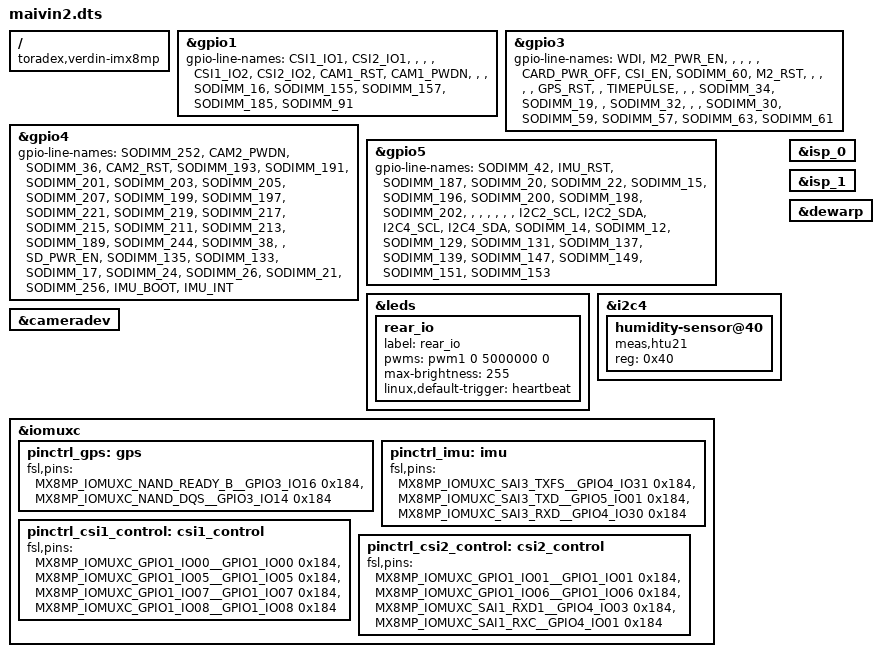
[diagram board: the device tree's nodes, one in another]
// SPDX-License-Identifier: AGPL-3.0
/*
 * Copyright 2023 Au-Zone Technologies
 */

// Maivin 2 Overlays

/dts-v1/;
/plugin/;

#include <dt-bindings/clock/imx8mp-clock.h>
#include <dt-bindings/gpio/gpio.h>

#include "imx8mp-pinfunc.h"

/ {
	compatible = "toradex,verdin-imx8mp";
};

&gpio1 {
	gpio-line-names = "CSI1_IO1", /* SODIMM_206 */
			  "CSI2_IO1", /* SODIMM_208 */
			  "",
			  "",
			  "",
			  "CSI1_IO2", /* SODIMM_210 */
			  "CSI2_IO2", /* SODIMM_212 */
			  "CAM1_RST", /* SODIMM_216 */
			  "CAM1_PWDN", /* SODIMM_218 */
			  "",
			  "",
			  "SODIMM_16",
			  "SODIMM_155",
			  "SODIMM_157",
			  "SODIMM_185",
			  "SODIMM_91";
};

&gpio3 {
	gpio-line-names = "WDI", /* SODIMM_52 */
			  "M2_PWR_EN", /* SODIMM_54 */
			  "",
			  "",
			  "",
			  "",
			  "CARD_PWR_OFF", /* SODIMM_56 */
			  "CSI_EN", /* SODIMM_58 */
			  "SODIMM_60",
			  "M2_RST", /* SODIMM_62 */
			  "",
			  "",
			  "",
			  "",
			  "GPS_RST", /* SODIMM_66 */
			  "",
			  "TIMEPULSE", /* SODIMM_64 */
			  "",
			  "",
			  "SODIMM_34",
			  "SODIMM_19",
			  "",
			  "SODIMM_32",
			  "",
			  "",
			  "SODIMM_30",
			  "SODIMM_59",
			  "SODIMM_57",
			  "SODIMM_63",
			  "SODIMM_61";
};

&gpio4 {
	gpio-line-names = "SODIMM_252",
			  "CAM2_PWDN", /* SODIMM_222 */
			  "SODIMM_36",
			  "CAM2_RST", /* SODIMM_220 */
			  "SODIMM_193",
			  "SODIMM_191",
			  "SODIMM_201",
			  "SODIMM_203",
			  "SODIMM_205",
			  "SODIMM_207",
			  "SODIMM_199",
			  "SODIMM_197",
			  "SODIMM_221",
			  "SODIMM_219",
			  "SODIMM_217",
			  "SODIMM_215",
			  "SODIMM_211",
			  "SODIMM_213",
			  "SODIMM_189",
			  "SODIMM_244",
			  "SODIMM_38",
			  "",
			  "SD_PWR_EN", /* SODIMM_76 */
			  "SODIMM_135",
			  "SODIMM_133",
			  "SODIMM_17",
			  "SODIMM_24",
			  "SODIMM_26",
			  "SODIMM_21",
			  "SODIMM_256",
			  "IMU_BOOT", /* SODIMM_48 */
			  "IMU_INT"; /* SODIMM_44 */
};

&gpio5 {
	gpio-line-names = "SODIMM_42",
			  "IMU_RST", /* SODIMM_46 */
			  "SODIMM_187",
			  "SODIMM_20",
			  "SODIMM_22",
			  "SODIMM_15",
			  "SODIMM_196",
			  "SODIMM_200",
			  "SODIMM_198",
			  "SODIMM_202",
			  "",
			  "",
			  "",
			  "",
			  "",
			  "",
			  "I2C2_SCL", /* SODIMM_55 */
			  "I2C2_SDA", /* SODIMM_53 */
			  "I2C4_SCL", /* SODIMM_95 */
			  "I2C4_SDA", /* SODIMM_93 */
			  "SODIMM_14",
			  "SODIMM_12",
			  "SODIMM_129",
			  "SODIMM_131",
			  "SODIMM_137",
			  "SODIMM_139",
			  "SODIMM_147",
			  "SODIMM_149",
			  "SODIMM_151",
			  "SODIMM_153";
};

&leds {
	rear_io {
		label = "rear_io";
		pwms = <&pwm1 0 5000000 0>;
		max-brightness = <255>;
		linux,default-trigger = "heartbeat";
	};
};

/* Verdin I2C_1 */
&i2c4 {
	#address-cells = <1>;
	#size-cells = <0>;
	status = "okay";

	humidity-sensor@40 {
		compatible = "meas,htu21";
		reg = <0x40>;
	};
};

&cameradev {
	status = "okay";
};

&isp_0 {
	status = "okay";
};

&isp_1 {
	status = "okay";
};

&dewarp {
	status = "okay";
};

&iomuxc {
	/* GPS Controls */
	pinctrl_gps: gps {
		fsl,pins =
			<MX8MP_IOMUXC_NAND_READY_B__GPIO3_IO16		0x184>, /* SODIMM 64 - TIMEPULSE */
			<MX8MP_IOMUXC_NAND_DQS__GPIO3_IO14		0x184>; /* SODIMM 66 - GPS_RST */
	};

	/* IMU Controls */
	pinctrl_imu: imu {
		fsl,pins =
			<MX8MP_IOMUXC_SAI3_TXFS__GPIO4_IO31		0x184>, /* SODIMM 44 - IMU_INT */
			<MX8MP_IOMUXC_SAI3_TXD__GPIO5_IO01		0x184>, /* SODIMM 46 - IMU_RST */
			<MX8MP_IOMUXC_SAI3_RXD__GPIO4_IO30		0x184>; /* SODIMM 48 - IMU_BOOT */
	};

	/* CSI-1 Controls */
	pinctrl_csi1_control: csi1_control {
		fsl,pins =
			<MX8MP_IOMUXC_GPIO1_IO00__GPIO1_IO00		0x184>,	/* SODIMM 206 - CSI1_IO1 */
			<MX8MP_IOMUXC_GPIO1_IO05__GPIO1_IO05		0x184>,	/* SODIMM 210 - CSI1_IO2 */
			<MX8MP_IOMUXC_GPIO1_IO07__GPIO1_IO07		0x184>,	/* SODIMM 216 - CAM1_RST - CSI-1 Reset */
			<MX8MP_IOMUXC_GPIO1_IO08__GPIO1_IO08		0x184>;	/* SODIMM 218 - CAM1_PWDN - CSI-1 Power Down */
	};

	/* CSI-2 Controls */
	pinctrl_csi2_control: csi2_control {
		fsl,pins =
			<MX8MP_IOMUXC_GPIO1_IO01__GPIO1_IO01		0x184>,	/* SODIMM 208 - CSI2_IO1 */
			<MX8MP_IOMUXC_GPIO1_IO06__GPIO1_IO06		0x184>,	/* SODIMM 212 - CSI2_IO2 */
			<MX8MP_IOMUXC_SAI1_RXD1__GPIO4_IO03		0x184>,	/* SODIMM 220 - CAM2_RST - CSI-2 Reset */
			<MX8MP_IOMUXC_SAI1_RXC__GPIO4_IO01		0x184>;	/* SODIMM 222 - CAM2_PWDN - CSI-2 Power Down */
	};
};
